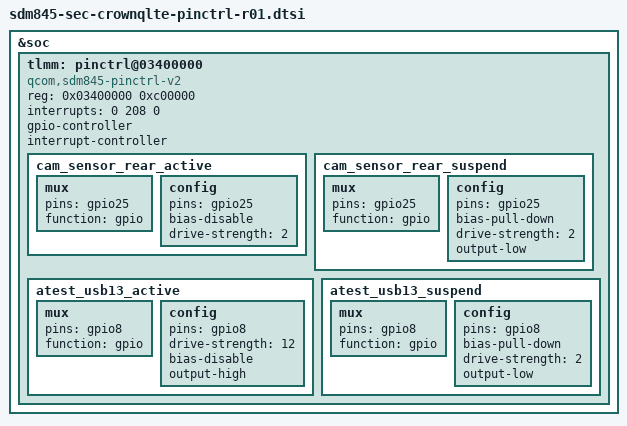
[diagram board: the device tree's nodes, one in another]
/* Copyright (c) 2016-2017, The Linux Foundation. All rights reserved.
 *
 * This program is free software; you can redistribute it and/or modify
 * it under the terms of the GNU General Public License version 2 and
 * only version 2 as published by the Free Software Foundation.
 *
 * This program is distributed in the hope that it will be useful,
 * but WITHOUT ANY WARRANTY; without even the implied warranty of
 * MERCHANTABILITY or FITNESS FOR A PARTICULAR PURPOSE.  See the
 * GNU General Public License for more details.
 */

#include "sdm845-sec-crownqlte-pinctrl-common.dtsi"

&soc {
	tlmm: pinctrl@03400000 {
		compatible = "qcom,sdm845-pinctrl-v2";
		reg = <0x03400000 0xc00000>;
		interrupts = <0 208 0>;
		gpio-controller;
		#gpio-cells = <2>;
		interrupt-controller;
		#interrupt-cells = <2>;

		cam_sensor_rear_active: cam_sensor_rear_active {
			/* RESET */
			mux {
				pins = "gpio25";
				function = "gpio";
			};

			config {
				pins = "gpio25";
				bias-disable; /* No PULL */
				drive-strength = <2>; /* 2 MA */
			};
		};

		cam_sensor_rear_suspend: cam_sensor_rear_suspend {
			/* RESET */
			mux {
				pins = "gpio25";
				function = "gpio";
			};

			config {
				pins = "gpio25";
				bias-pull-down; /* PULL DOWN */
				drive-strength = <2>; /* 2 MA */
				output-low;
			};
		};
		
		atest_usb13_active: atest_usb13_active {
			mux {
				pins = "gpio8";
				function = "gpio";
			};
			config {
				pins = "gpio8";
				drive-strength = <12>;
				bias-disable;
				output-high;
			};
		};

		atest_usb13_suspend: atest_usb13_suspend {
			mux {
				pins = "gpio8";
				function = "gpio";
			};
			config {
				pins = "gpio8";
				bias-pull-down;
				drive-strength = <2>;
				output-low;
			};
		};
	};
};
